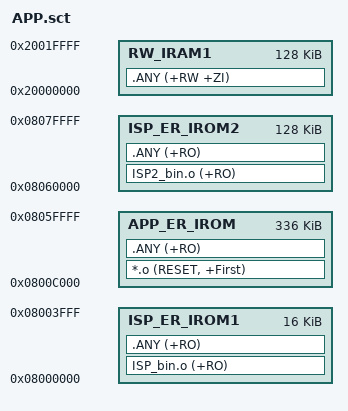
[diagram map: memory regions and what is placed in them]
; *************************************************************
; *** Scatter-Loading Description File generated by uVision ***
; *************************************************************

ISP_IROM1 0x08000000 0x00004000  {    ; load region size_region
  ISP_ER_IROM1 0x08000000 0x00004000{  ; load address = execution address
   ISP_bin.o (+RO)
   .ANY (+RO)
  }
}

APP_IROM 0x0800C000 0x00054000  {
  APP_ER_IROM 0x0800C000 0x00054000  {  ; load address = execution address
   *.o (RESET, +First)
   .ANY (+RO)
  }
  RW_IRAM1 0x20000000 0x00020000  {  ; RW data
   .ANY (+RW +ZI)
  }
}

ISP_IROM2 0x08060000 0x00020000  {    ; load region size_region
  ISP_ER_IROM2 0x08060000 0x00020000{  ; load address = execution address
   ISP2_bin.o (+RO)
   .ANY (+RO)
  }
}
